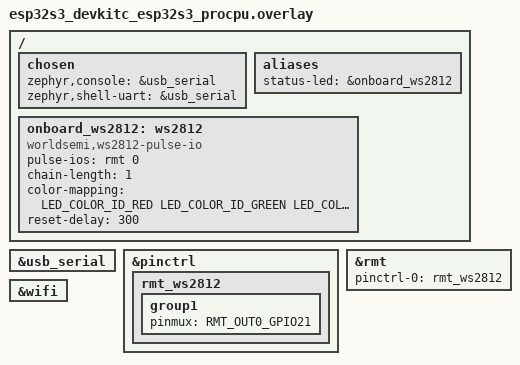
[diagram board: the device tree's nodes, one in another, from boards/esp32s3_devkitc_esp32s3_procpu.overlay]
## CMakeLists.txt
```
cmake_minimum_required(VERSION 3.20.0)

find_package(Zephyr REQUIRED HINTS $ENV{ZEPHYR_BASE})
project(nachtlicht)

target_sources(app PRIVATE
  src/main.cpp
  src/connectivity/connectivity.cpp
  src/rgb_led/rgb_led.cpp
  src/zenoh_client/zenoh_client.cpp
)
target_include_directories(app PRIVATE src)
```

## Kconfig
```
mainmenu "nachtlicht"

source "Kconfig.zephyr"

menu "nachtlicht"

config NACHTLICHT_WIFI_SSID
	string "Wi-Fi SSID"
	default ""
	help
	  SSID of the WPA2-PSK network used by the connectivity demonstration.

config NACHTLICHT_WIFI_PSK
	string "Wi-Fi pre-shared key"
	default ""
	help
	  WPA2 pre-shared key of the Wi-Fi network used by the connectivity
	  demonstration.

config NACHTLICHT_ZENOH_P2P_PEER_LOCATOR
	string "Direct Zenoh peer locator"
	default ""
	help
	  TCP locator of the Dilbert peer used for the direct peer-to-peer
	  demonstration. Set it in the ignored zenoh.conf file.

endmenu
```

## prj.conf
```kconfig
CONFIG_CPP=y
CONFIG_STD_CPP17=y
CONFIG_REQUIRES_FULL_LIBCPP=y
CONFIG_CONSOLE=y
CONFIG_PRINTK=y
CONFIG_SERIAL=y
CONFIG_UART_CONSOLE=y
CONFIG_LED_STRIP=y
CONFIG_PULSE_IO=y
CONFIG_WS2812_STRIP_PULSE_IO=y
CONFIG_PULSE_IO_ESP32_RMT=y
CONFIG_NETWORKING=y
CONFIG_NET_IPV4=y
CONFIG_NET_TCP=y
CONFIG_NET_UDP=y
CONFIG_NET_DHCPV4=y
CONFIG_NET_MGMT=y
CONFIG_NET_MGMT_EVENT=y
CONFIG_NET_L2_ETHERNET=y
CONFIG_ETH_DRIVER=n
CONFIG_NET_L2_WIFI_MGMT=y
CONFIG_WIFI=y
CONFIG_WIFI_NM=y
CONFIG_WIFI_STA_AUTO_DHCPV4=n
CONFIG_LOG=y
CONFIG_WIFI_LOG_LEVEL_DBG=n

# zenoh-pico Zephyr module: TCP client with the threading support required by
# its Zephyr platform layer. The application uses Publisher and Subscriber APIs.
CONFIG_ZENOH_PICO=y
CONFIG_ZENOH_PICO_LINK_TCP=y
CONFIG_ZENOH_PICO_LINK_UDP_MULTICAST=y
CONFIG_ZENOH_PICO_LINK_UDP_UNICAST=y
CONFIG_ZENOH_PICO_MULTI_THREAD=y
CONFIG_ZENOH_PICO_PUBLICATION=y
CONFIG_ZENOH_PICO_SCOUTING=y
CONFIG_ZENOH_PICO_SUBSCRIPTION=y
CONFIG_POSIX_API=y

# zenoh-pico creates session, transport and executor synchronization objects.
# Zephyr's POSIX defaults of five mutexes are insufficient for one session.
CONFIG_POSIX_THREAD_THREADS_MAX=8
CONFIG_MAX_PTHREAD_MUTEX_COUNT=16
CONFIG_MAX_PTHREAD_COND_COUNT=8
```

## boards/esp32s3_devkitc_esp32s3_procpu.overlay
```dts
#include <zephyr/dt-bindings/led/led.h>

/ {
	chosen {
		zephyr,console = &usb_serial;
		zephyr,shell-uart = &usb_serial;
	};

	aliases {
		status-led = &onboard_ws2812;
	};

	onboard_ws2812: ws2812 {
		compatible = "worldsemi,ws2812-pulse-io";
		pulse-ios = <&rmt 0>;
		chain-length = <1>;
		color-mapping = <LED_COLOR_ID_RED LED_COLOR_ID_GREEN LED_COLOR_ID_BLUE>;
		reset-delay = <300>;
	};
};

&usb_serial {
	status = "okay";
};

&pinctrl {
	rmt_ws2812: rmt_ws2812 {
		group1 {
			pinmux = <RMT_OUT0_GPIO21>;
		};
	};
};

&rmt {
	pinctrl-0 = <&rmt_ws2812>;
	pinctrl-names = "default";
	status = "okay";
};

&wifi {
	status = "okay";
};
```

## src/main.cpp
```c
#include <zephyr/kernel.h>
#include <zephyr/sys/atomic.h>
#include <zephyr/sys/printk.h>

#include <array>
#include <atomic>
#include <cstddef>
#include <cstdint>

#include "connectivity/connectivity.hpp"
#include "rgb_led/rgb_led.hpp"
#include "zenoh_client/zenoh_client.hpp"

namespace
{

// clang-format off
struct TestColor
{
  rgb_led::Color value;
  const char *name;
};

constexpr std::array<TestColor, 6> kTestColors{{
    { { 255U,   0U,   0U }, "red" },
    { { 255U, 255U,   0U }, "yellow" },
    { {   0U, 255U,   0U }, "green" },
    { {   0U, 255U, 255U }, "cyan" },
    { {   0U,   0U, 255U }, "blue" },
    { { 255U,   0U, 255U }, "magenta" },
}};
// clang-format on

constexpr std::uint8_t kColorChangedEvent = BIT(0);
constexpr std::uint8_t kBrightnessChangedEvent = BIT(1);

rgb_led::RgbLed led;
connectivity::Connectivity network;
zenoh_client::ZenohClient zenoh;
struct k_work color_work;
std::size_t color_index;

struct k_work render_work;

constexpr std::uint8_t kBrightnessOn = 32U;
constexpr std::uint8_t kBrightnessOff = 0U;
constexpr std::uint16_t kBrightnessMaximum = 255U;
std::atomic<std::uint8_t> brightness{kBrightnessOn};  // std::atomic for clean thread-safe implementation
struct k_timer brightness_timer;

rgb_led::Color current_color;
const char *current_color_name;
std::atomic<std::uint8_t> pending_events{0U};
std::uint32_t color_change_sequence;
std::uint32_t brightness_change_sequence;

void render_color(struct k_work *work)
{
  ARG_UNUSED(work);
  rgb_led::Color c = current_color;
  const auto brightness_value = brightness.load();

  c.red = static_cast<std::uint8_t>((static_cast<std::uint16_t>(c.red) * brightness_value) / kBrightnessMaximum);
  c.green = static_cast<std::uint8_t>((static_cast<std::uint16_t>(c.green) * brightness_value) / kBrightnessMaximum);
  c.blue = static_cast<std::uint8_t>((static_cast<std::uint16_t>(c.blue) * brightness_value) / kBrightnessMaximum);

  const auto result = led.set(c);
  if (result != 0)
  {
    printk("RGB LED update failed: %d\n", result);
    return;
  }

  const auto events = pending_events.exchange(0U);
  if ((events & kColorChangedEvent) != 0U)
  {
    zenoh.publish_color_changed(++color_change_sequence, current_color_name);
  }
  if ((events & kBrightnessChangedEvent) != 0U)
  {
    zenoh.publish_brightness_changed(++brightness_change_sequence, brightness_value);
  }
}

void update_brightness(struct k_timer *timer)
{
  ARG_UNUSED(timer);
  const auto next_brightness = brightness.load() == kBrightnessOn ? kBrightnessOff : kBrightnessOn;
  brightness.store(next_brightness);
  pending_events.fetch_or(kBrightnessChangedEvent);
  k_work_submit(&render_work);
}

void update_color(struct k_work *work)
{
  ARG_UNUSED(work);
  const auto &next_color = kTestColors[color_index];
  current_color = next_color.value;
  current_color_name = next_color.name;
  color_index = (color_index + 1U) % kTestColors.size();
  pending_events.fetch_or(kColorChangedEvent);
  k_work_submit(&render_work);
}

void request_next_color(void *context)
{
  auto *const work = static_cast<struct k_work *>(context);
  k_work_submit(work);
}

void start_zenoh(void *context)
{
  auto *const client = static_cast<zenoh_client::ZenohClient *>(context);
  client->start();
}

}  // namespace

int main()
{
  printk("Hello World from nachtlicht!\n");

  const auto result = led.initialize();
  if (result != 0)
  {
    printk("RGB LED initialization failed: %d\n", result);
    return result;
  }

  printk("RGB LED test started.\n");
  k_work_init(&color_work, update_color);
  k_work_init(&render_work, render_color);
  k_timer_init(&brightness_timer, update_brightness, nullptr);

  k_work_submit(&color_work);
  k_timer_start(&brightness_timer, K_MSEC(500), K_MSEC(500));

  zenoh.initialize(request_next_color, &color_work);
  const auto connectivity_result = network.initialize(start_zenoh, &zenoh);
  if (connectivity_result != 0)
  {
    printk("Connectivity initialization failed: %d\n", connectivity_result);
  }

  return 0;
}
```
